# STM32L151 register map
File version: 1.5
CPU: CM3 r1p1, little endian, no MPU, no FPU, 4 interrupt priority bits
Registers are 32-bit, read-write, reset 0x0 unless marked. A register's access mark holds for its fields unless they carry their own. Offsets are from the block's base; [hi:lo] are bit positions; {n}, {i} and the like mark numbered series; 'fields as' and 'values as' point back to an identical list.

## FSMC — Flexible static memory controller
Base 0xA0000000
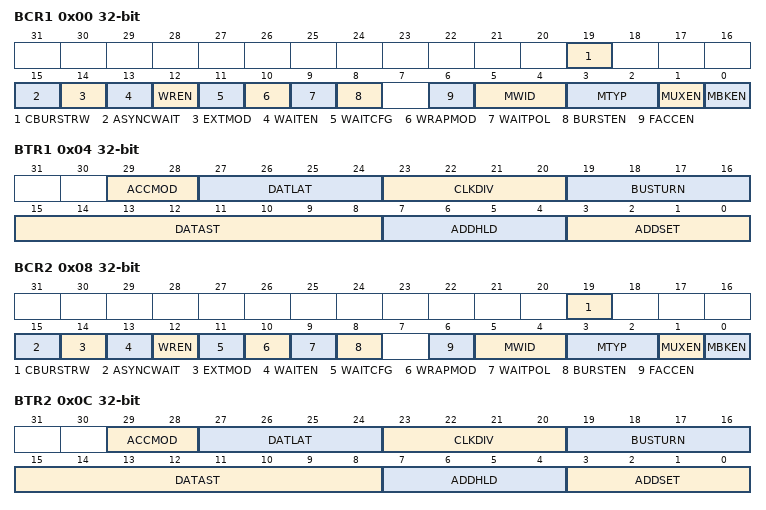
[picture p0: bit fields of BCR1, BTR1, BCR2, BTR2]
0x00 BCR1
  [19] CBURSTRW, [15] ASYNCWAIT, [14] EXTMOD, [13] WAITEN, [12] WREN, [11] WAITCFG, [10] WRAPMOD, [9] WAITPOL, [8] BURSTEN, [6] FACCEN, [5:4] MWID, [3:2] MTYP, [1] MUXEN, [0] MBKEN
0x04 BTR1
  [29:28] ACCMOD, [27:24] DATLAT, [23:20] CLKDIV, [19:16] BUSTURN, [15:8] DATAST, [7:4] ADDHLD, [3:0] ADDSET
0x08 BCR2
  fields as BCR1
0x0C BTR2
  fields as BTR1
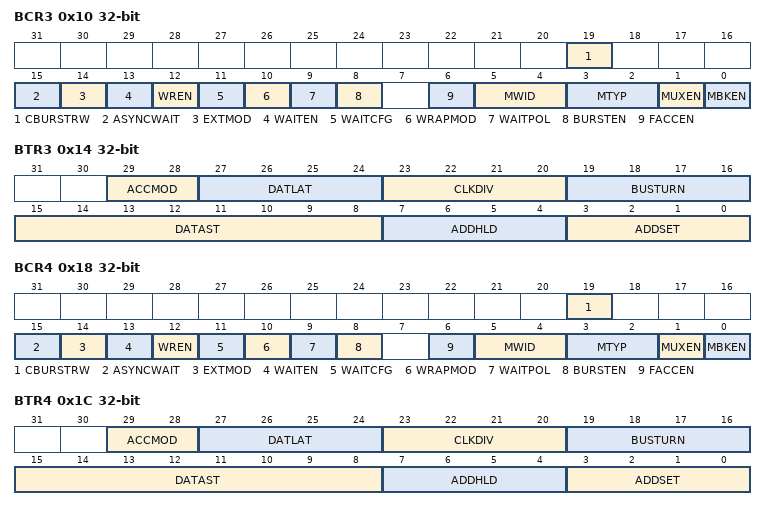
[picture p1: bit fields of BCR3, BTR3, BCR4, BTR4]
0x10 BCR3
  fields as BCR1
0x14 BTR3
  fields as BTR1
0x18 BCR4
  fields as BCR1
0x1C BTR4
  fields as BTR1
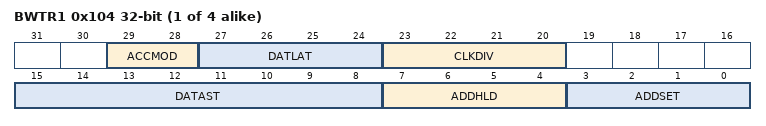
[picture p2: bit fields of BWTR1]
{0xFC+8i} BWTR{i} (i=1..4)
  [29:28] ACCMOD, [27:24] DATLAT, [23:20] CLKDIV, [15:8] DATAST, [7:4] ADDHLD, [3:0] ADDSET

## GPIOA — General-purpose I/Os
Base 0x40020000
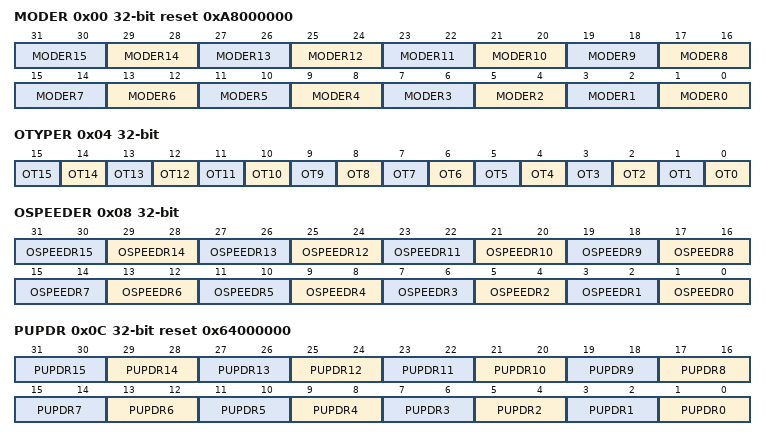
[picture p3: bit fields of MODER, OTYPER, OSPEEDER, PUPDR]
0x00 MODER reset 0xA8000000 — GPIO port mode register
  [2n+1:2n] MODER{n} (n=0..15) — Port x configuration bits (y = 0..15)
0x04 OTYPER — GPIO port output type register
  [n] OT{n} (n=0..15) — Port x configuration bits (y = 0..15)
0x08 OSPEEDER — GPIO port output speed register
  [2n+1:2n] OSPEEDR{n} (n=0..15)
0x0C PUPDR reset 0x64000000 — GPIO port pull-up/pull-down register
  [2n+1:2n] PUPDR{n} (n=0..15) — Port x configuration bits (y = 0..15)
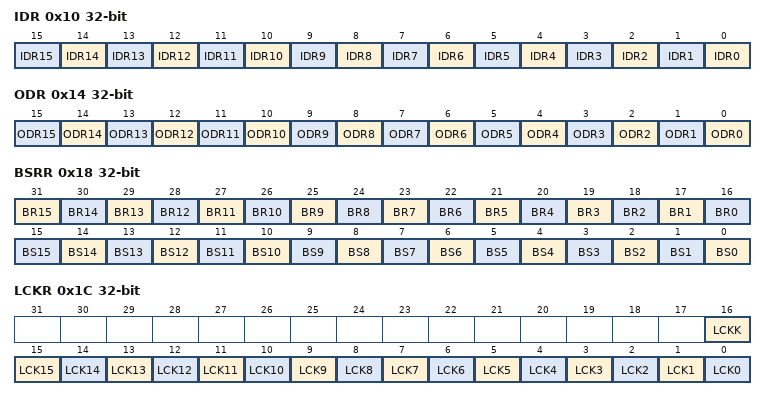
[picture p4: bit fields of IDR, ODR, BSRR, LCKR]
0x10 IDR ro — GPIO port input data register
  [n] IDR{n} (n=0..15) — Port input data (y = 0..15)
0x14 ODR — GPIO port output data register
  [n] ODR{n} (n=0..15) — Port output data (y = 0..15)
0x18 BSRR wo — GPIO port bit set/reset register
  [n+16] BR{n} (n=1..15) — Port x reset bit y (y = 0..15)
  [16] BR0 — Port x set bit y (y= 0..15)
  [n] BS{n} (n=0..15) — Port x set bit y (y= 0..15)
0x1C LCKR — GPIO port configuration lock register
  [16] LCKK — Port x lock bit y (y= 0..15)
  [n] LCK{n} (n=0..15) — Port x lock bit y (y= 0..15)
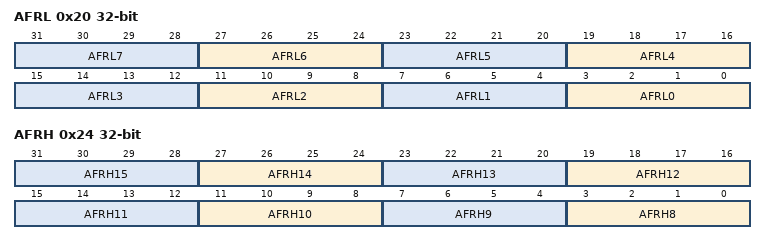
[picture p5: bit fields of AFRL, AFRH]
0x20 AFRL
  [4n+3:4n] AFRL{n} (n=0..7) — Alternate function selection for port x bit y (y = 0..7)
0x24 AFRH — GPIO alternate function high register
  [4n-29:4n-32] AFRH{n} (n=8..15) — Alternate function selection for port x bit y (y = 8..15)

## GPIOB — General-purpose I/Os
Base 0x40020400
Registers as GPIOA; these are added or differ:
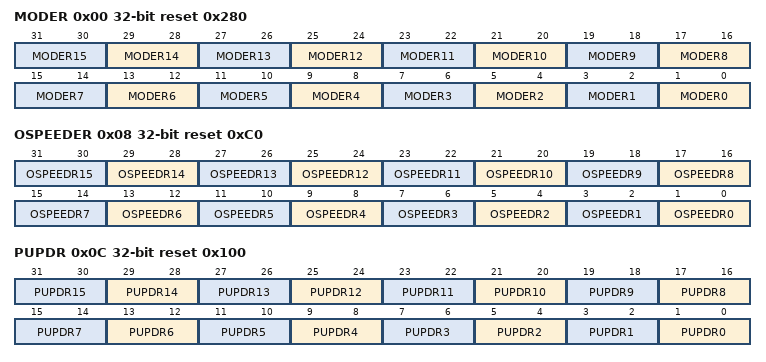
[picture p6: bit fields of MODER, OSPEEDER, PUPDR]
0x00 MODER reset 0x280 — GPIO port mode register
  [2n+1:2n] MODER{n} (n=0..15) — Port x configuration bits (y = 0..15)
0x08 OSPEEDER reset 0xC0 — GPIO port output speed register
  [2n+1:2n] OSPEEDR{n} (n=0..15)
0x0C PUPDR reset 0x100 — GPIO port pull-up/pull-down register
  [2n+1:2n] PUPDR{n} (n=0..15) — Port x configuration bits (y = 0..15)

## GPIOC — General-purpose I/Os
Base 0x40020800
Same registers: GPIOD 0x40020C00, GPIOE 0x40021000, GPIOH 0x40021400, GPIOF 0x40021800, GPIOG 0x40021C00
Registers as GPIOA; these are added or differ:
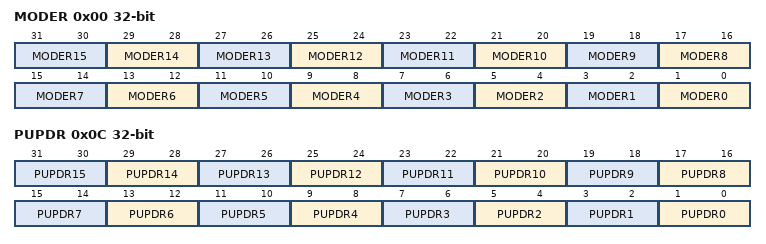
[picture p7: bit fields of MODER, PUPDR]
0x00 MODER — GPIO port mode register
  [2n+1:2n] MODER{n} (n=0..15) — Port x configuration bits (y = 0..15)
0x0C PUPDR — GPIO port pull-up/pull-down register
  [2n+1:2n] PUPDR{n} (n=0..15) — Port x configuration bits (y = 0..15)

## I2C1 — Inter-integrated circuit
Base 0x40005400
Same registers: I2C2 0x40005800
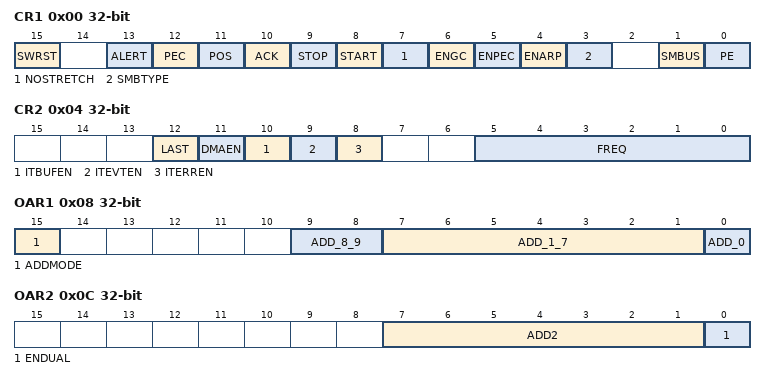
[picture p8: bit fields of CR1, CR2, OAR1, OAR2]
0x00 CR1
  [15] SWRST — Software reset
  [13] ALERT — SMBus alert
  [12] PEC — Packet error checking
  [11] POS — Acknowledge/PEC Position (for data reception)
  [10] ACK — Acknowledge enable
  [9] STOP — Stop generation
  [8] START — Start generation
  [7] NOSTRETCH — Clock stretching disable (Slave mode)
  [6] ENGC — General call enable
  [5] ENPEC — PEC enable
  [4] ENARP — ARP enable
  [3] SMBTYPE — SMBus type
  [1] SMBUS — SMBus mode
  [0] PE — Peripheral enable
0x04 CR2
  [12] LAST — DMA last transfer
  [11] DMAEN — DMA requests enable
  [10] ITBUFEN — Buffer interrupt enable
  [9] ITEVTEN — Event interrupt enable
  [8] ITERREN — Error interrupt enable
  [5:0] FREQ — Peripheral clock frequency
0x08 OAR1
  [15] ADDMODE
  [9:8] ADD_8_9 — Interface address
  [7:1] ADD_1_7 — Interface address
  [0] ADD_0 — Interface address
0x0C OAR2
  [7:1] ADD2 — Interface address
  [0] ENDUAL — Dual addressing mode enable
0x10 DR
  [7:0] DR — -bit data register
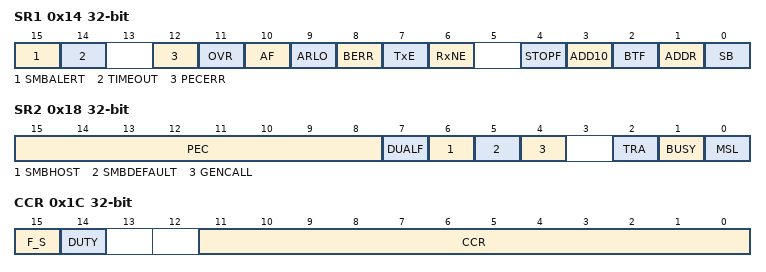
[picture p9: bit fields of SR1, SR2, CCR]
0x14 SR1 access per field
  [15] SMBALERT rw — SMBus alert
  [14] TIMEOUT rw — Timeout or Tlow error
  [12] PECERR rw — PEC Error in reception
  [11] OVR rw — Overrun/Underrun
  [10] AF rw — Acknowledge failure
  [9] ARLO rw — Arbitration lost (master mode)
  [8] BERR rw — Bus error
  [7] TxE ro — Data register empty (transmitters)
  [6] RxNE ro — Data register not empty (receivers)
  [4] STOPF ro — Stop detection (slave mode)
  [3] ADD10 ro — 10-bit header sent (Master mode)
  [2] BTF ro — Byte transfer finished
  [1] ADDR ro — Address sent (master mode)/matched (slave mode)
  [0] SB ro — Start bit (Master mode)
0x18 SR2 ro
  [15:8] PEC — acket error checking register
  [7] DUALF — Dual flag (Slave mode)
  [6] SMBHOST — SMBus host header (Slave mode)
  [5] SMBDEFAULT — SMBus device default address (Slave mode)
  [4] GENCALL — General call address (Slave mode)
  [2] TRA — Transmitter/receiver
  [1] BUSY — Bus busy
  [0] MSL — Master/slave
0x1C CCR
  [15] F_S — I2C master mode selection
  [14] DUTY — Fast mode duty cycle
  [11:0] CCR — Clock control register in Fast/Standard mode (Master mode)
0x20 TRISE reset 0x2
  [5:0] TRISE — Maximum rise time in Fast/Standard mode (Master mode)
